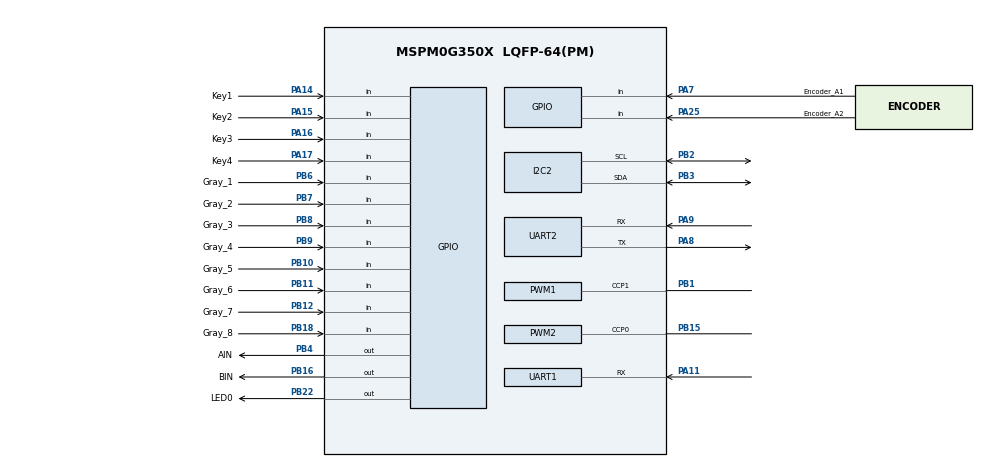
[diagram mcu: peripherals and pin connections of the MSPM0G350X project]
/**
 * @cliArgs --device "MSPM0G350X" --part "Default" --package "LQFP-64(PM)" --product "mspm0_sdk@2.10.00.04"
 * @versions {"tool":"1.26.2+4477"}
 */

/**
 * Import the modules used in this configuration.
 */
const GPIO   = scripting.addModule("/ti/driverlib/GPIO", {}, false);
const GPIO1  = GPIO.addInstance();
const GPIO2  = GPIO.addInstance();
const GPIO3  = GPIO.addInstance();
const GPIO4  = GPIO.addInstance();
const GPIO5  = GPIO.addInstance();
const I2C    = scripting.addModule("/ti/driverlib/I2C", {}, false);
const I2C1   = I2C.addInstance();
const I2C2   = I2C.addInstance();
const PWM    = scripting.addModule("/ti/driverlib/PWM", {}, false);
const PWM1   = PWM.addInstance();
const PWM2   = PWM.addInstance();
const SYSCTL = scripting.addModule("/ti/driverlib/SYSCTL");
const TIMER  = scripting.addModule("/ti/driverlib/TIMER", {}, false);
const TIMER1 = TIMER.addInstance();
const TIMER2 = TIMER.addInstance();
const UART   = scripting.addModule("/ti/driverlib/UART", {}, false);
const UART1  = UART.addInstance();
const UART2  = UART.addInstance();

/**
 * Write custom configuration values to the imported modules.
 */
const divider9       = system.clockTree["UDIV"];
divider9.divideValue = 2;

const multiplier2         = system.clockTree["PLL_QDIV"];
multiplier2.multiplyValue = 5;

const mux4       = system.clockTree["EXHFMUX"];
mux4.inputSelect = "EXHFMUX_XTAL";

const mux8       = system.clockTree["HSCLKMUX"];
mux8.inputSelect = "HSCLKMUX_SYSPLL0";

const pinFunction4     = system.clockTree["HFXT"];
pinFunction4.inputFreq = 40;
pinFunction4.enable    = true;

GPIO1.$name                         = "LED";
GPIO1.associatedPins[0].$name       = "LED0";
GPIO1.associatedPins[0].pin.$assign = "PB22";

const Board = scripting.addModule("/ti/driverlib/Board", {}, false);

GPIO2.$name                         = "Keys";
GPIO2.port                          = "PORTA";
GPIO2.associatedPins.create(4);
GPIO2.associatedPins[0].$name       = "Key1";
GPIO2.associatedPins[0].direction   = "INPUT";
GPIO2.associatedPins[0].pin.$assign = "PA14";
GPIO2.associatedPins[1].$name       = "Key2";
GPIO2.associatedPins[1].direction   = "INPUT";
GPIO2.associatedPins[1].pin.$assign = "PA15";
GPIO2.associatedPins[2].$name       = "Key3";
GPIO2.associatedPins[2].direction   = "INPUT";
GPIO2.associatedPins[2].pin.$assign = "PA16";
GPIO2.associatedPins[3].$name       = "Key4";
GPIO2.associatedPins[3].direction   = "INPUT";
GPIO2.associatedPins[3].pin.$assign = "PA17";

GPIO3.$name                         = "Gray";
GPIO3.associatedPins.create(8);
GPIO3.associatedPins[0].$name       = "Gray_1";
GPIO3.associatedPins[0].direction   = "INPUT";
GPIO3.associatedPins[0].pin.$assign = "PB6";
GPIO3.associatedPins[1].$name       = "Gray_2";
GPIO3.associatedPins[1].direction   = "INPUT";
GPIO3.associatedPins[1].pin.$assign = "PB7";
GPIO3.associatedPins[2].$name       = "Gray_3";
GPIO3.associatedPins[2].direction   = "INPUT";
GPIO3.associatedPins[2].pin.$assign = "PB8";
GPIO3.associatedPins[3].$name       = "Gray_4";
GPIO3.associatedPins[3].direction   = "INPUT";
GPIO3.associatedPins[3].pin.$assign = "PB9";
GPIO3.associatedPins[4].$name       = "Gray_5";
GPIO3.associatedPins[4].direction   = "INPUT";
GPIO3.associatedPins[4].pin.$assign = "PB10";
GPIO3.associatedPins[5].$name       = "Gray_6";
GPIO3.associatedPins[5].direction   = "INPUT";
GPIO3.associatedPins[5].pin.$assign = "PB11";
GPIO3.associatedPins[6].$name       = "Gray_7";
GPIO3.associatedPins[6].direction   = "INPUT";
GPIO3.associatedPins[6].pin.$assign = "PB12";
GPIO3.associatedPins[7].$name       = "Gray_8";
GPIO3.associatedPins[7].direction   = "INPUT";
GPIO3.associatedPins[7].pin.$assign = "PB18";

GPIO4.$name                         = "Motors";
GPIO4.associatedPins.create(2);
GPIO4.associatedPins[0].$name       = "AIN";
GPIO4.associatedPins[0].pin.$assign = "PB4";
GPIO4.associatedPins[1].$name       = "BIN";
GPIO4.associatedPins[1].pin.$assign = "PB16";

GPIO5.$name                               = "Encoders";
GPIO5.associatedPins.create(4);
GPIO5.associatedPins[0].$name             = "Encoder_A1";
GPIO5.associatedPins[0].direction         = "INPUT";
GPIO5.associatedPins[0].interruptEn       = true;
GPIO5.associatedPins[0].interruptPriority = "0";
GPIO5.associatedPins[0].polarity          = "RISE";
GPIO5.associatedPins[0].internalResistor  = "PULL_DOWN";
GPIO5.associatedPins[0].pin.$assign       = "PA7";
GPIO5.associatedPins[1].$name             = "Encoder_A2";
GPIO5.associatedPins[1].direction         = "INPUT";
GPIO5.associatedPins[1].interruptEn       = true;
GPIO5.associatedPins[1].interruptPriority = "0";
GPIO5.associatedPins[1].polarity          = "RISE";
GPIO5.associatedPins[1].internalResistor  = "PULL_DOWN";
GPIO5.associatedPins[1].pin.$assign       = "PA25";
GPIO5.associatedPins[2].$name             = "Encoder_B1";
GPIO5.associatedPins[2].direction         = "INPUT";
GPIO5.associatedPins[2].interruptEn       = true;
GPIO5.associatedPins[2].interruptPriority = "0";
GPIO5.associatedPins[2].polarity          = "RISE";
GPIO5.associatedPins[2].internalResistor  = "PULL_DOWN";
GPIO5.associatedPins[3].$name             = "Encoder_B2";
GPIO5.associatedPins[3].direction         = "INPUT";
GPIO5.associatedPins[3].interruptEn       = true;
GPIO5.associatedPins[3].interruptPriority = "0";
GPIO5.associatedPins[3].polarity          = "RISE";
GPIO5.associatedPins[3].internalResistor  = "PULL_DOWN";

I2C1.$name                             = "OLED";
I2C1.basicEnableController             = true;
I2C1.advDigitalGlitchFilter            = "CLOCKS_1";
I2C1.advControllerRXFIFOTRIG           = "BYTES_8";
I2C1.advControllerTXFIFOTRIG           = "BYTES_7";
I2C1.enableDMAEvent1                   = false;
I2C1.enableDMAEvent2                   = false;
I2C1.basicControllerStandardBusSpeed   = "Fast";
I2C1.sdaPinConfig.$name                = "ti_driverlib_gpio_GPIOPinGeneric0";
I2C1.sdaPinConfig.hideOutputInversion  = scripting.forceWrite(false);
I2C1.sdaPinConfig.onlyInternalResistor = scripting.forceWrite(false);
I2C1.sdaPinConfig.passedPeripheralType = scripting.forceWrite("Digital");
I2C1.sclPinConfig.$name                = "ti_driverlib_gpio_GPIOPinGeneric1";
I2C1.sclPinConfig.hideOutputInversion  = scripting.forceWrite(false);
I2C1.sclPinConfig.onlyInternalResistor = scripting.forceWrite(false);
I2C1.sclPinConfig.passedPeripheralType = scripting.forceWrite("Digital");

I2C2.$name                             = "GY_87";
I2C2.basicEnableController             = true;
I2C2.peripheral.$assign                = "I2C1";
I2C2.peripheral.sdaPin.$assign         = "PB3";
I2C2.peripheral.sclPin.$assign         = "PB2";
I2C2.sdaPinConfig.hideOutputInversion  = scripting.forceWrite(false);
I2C2.sdaPinConfig.onlyInternalResistor = scripting.forceWrite(false);
I2C2.sdaPinConfig.passedPeripheralType = scripting.forceWrite("Digital");
I2C2.sdaPinConfig.$name                = "ti_driverlib_gpio_GPIOPinGeneric6";
I2C2.sclPinConfig.hideOutputInversion  = scripting.forceWrite(false);
I2C2.sclPinConfig.onlyInternalResistor = scripting.forceWrite(false);
I2C2.sclPinConfig.passedPeripheralType = scripting.forceWrite("Digital");
I2C2.sclPinConfig.$name                = "ti_driverlib_gpio_GPIOPinGeneric7";

PWM1.timerStartTimer                    = true;
PWM1.ccIndex                            = [1];
PWM1.pwmMode                            = "EDGE_ALIGN_UP";
PWM1.$name                              = "PWM_A";
PWM1.clockPrescale                      = 2;
PWM1.timerCount                         = 8000;
PWM1.ccp1PinConfig.direction            = scripting.forceWrite("OUTPUT");
PWM1.ccp1PinConfig.hideOutputInversion  = scripting.forceWrite(false);
PWM1.ccp1PinConfig.onlyInternalResistor = scripting.forceWrite(false);
PWM1.ccp1PinConfig.passedPeripheralType = scripting.forceWrite("Digital");
PWM1.ccp1PinConfig.$name                = "ti_driverlib_gpio_GPIOPinGeneric9";
PWM1.peripheral.$assign                 = "TIMA1";
PWM1.peripheral.ccp1Pin.$assign         = "PB1";
PWM1.PWM_CHANNEL_1.$name                = "ti_driverlib_pwm_PWMTimerCC0";

PWM2.timerStartTimer                    = true;
PWM2.ccIndex                            = [0];
PWM2.$name                              = "PWM_B";
PWM2.pwmMode                            = "EDGE_ALIGN_UP";
PWM2.timerCount                         = 8000;
PWM2.PWM_CHANNEL_0.$name                = "ti_driverlib_pwm_PWMTimerCC1";
PWM2.ccp0PinConfig.direction            = scripting.forceWrite("OUTPUT");
PWM2.ccp0PinConfig.hideOutputInversion  = scripting.forceWrite(false);
PWM2.ccp0PinConfig.onlyInternalResistor = scripting.forceWrite(false);
PWM2.ccp0PinConfig.passedPeripheralType = scripting.forceWrite("Digital");
PWM2.ccp0PinConfig.$name                = "ti_driverlib_gpio_GPIOPinGeneric8";
PWM2.peripheral.$assign                 = "TIMG8";
PWM2.peripheral.ccp0Pin.$assign         = "PB15";

SYSCTL.forceDefaultClkConfig = true;
SYSCTL.clockTreeEn           = true;

TIMER1.$name              = "TIMER_0";
TIMER1.timerClkDiv        = 8;
TIMER1.timerMode          = "PERIODIC";
TIMER1.interrupts         = ["ZERO"];
TIMER1.timerPeriod        = "1ms";
TIMER1.timerClkPrescale   = 100;
TIMER1.timerStartTimer    = true;
TIMER1.interruptPriority  = "1";
TIMER1.peripheral.$assign = "TIMG0";

TIMER2.timerClkDiv        = 8;
TIMER2.timerMode          = "PERIODIC";
TIMER2.interrupts         = ["ZERO"];
TIMER2.timerStartTimer    = true;
TIMER2.interruptPriority  = "1";
TIMER2.$name              = "TIMER_ENCODER";
TIMER2.timerPeriod        = "10ms";
TIMER2.peripheral.$assign = "TIMG12";

UART1.$name                                  = "UART_0";
UART1.targetBaudRate                         = 115200;
UART1.enabledInterrupts                      = ["RX"];
UART1.enableDMARX                            = false;
UART1.peripheral.rxPin.$assign               = "PA11";
UART1.peripheral.txPin.$assignAllowConflicts = "PA10";
UART1.txPinConfig.$name                      = "ti_driverlib_gpio_GPIOPinGeneric2";
UART1.rxPinConfig.$name                      = "ti_driverlib_gpio_GPIOPinGeneric3";

UART2.$name                    = "UART_1";
UART2.targetBaudRate           = 115200;
UART2.enabledInterrupts        = ["RX"];
UART2.peripheral.rxPin.$assign = "PA9";
UART2.peripheral.txPin.$assign = "PA8";
UART2.txPinConfig.$name        = "ti_driverlib_gpio_GPIOPinGeneric4";
UART2.rxPinConfig.$name        = "ti_driverlib_gpio_GPIOPinGeneric5";

/**
 * Pinmux solution for unlocked pins/peripherals. This ensures that minor changes to the automatic solver in a future
 * version of the tool will not impact the pinmux you originally saw.  These lines can be completely deleted in order to
 * re-solve from scratch.
 */
pinFunction4.peripheral.$suggestSolution           = "SYSCTL";
pinFunction4.peripheral.hfxInPin.$suggestSolution  = "PA5";
pinFunction4.peripheral.hfxOutPin.$suggestSolution = "PA6";
Board.peripheral.$suggestSolution                  = "DEBUGSS";
Board.peripheral.swclkPin.$suggestSolution         = "PA20";
Board.peripheral.swdioPin.$suggestSolution         = "PA19";
GPIO5.associatedPins[2].pin.$suggestSolution       = "PB13";
GPIO5.associatedPins[3].pin.$suggestSolution       = "PB14";
I2C1.peripheral.$suggestSolution                   = "I2C0";
I2C1.peripheral.sdaPin.$suggestSolution            = "PA0";
I2C1.peripheral.sclPin.$suggestSolution            = "PA1";
UART1.peripheral.$suggestSolution                  = "UART0";
UART2.peripheral.$suggestSolution                  = "UART1";
